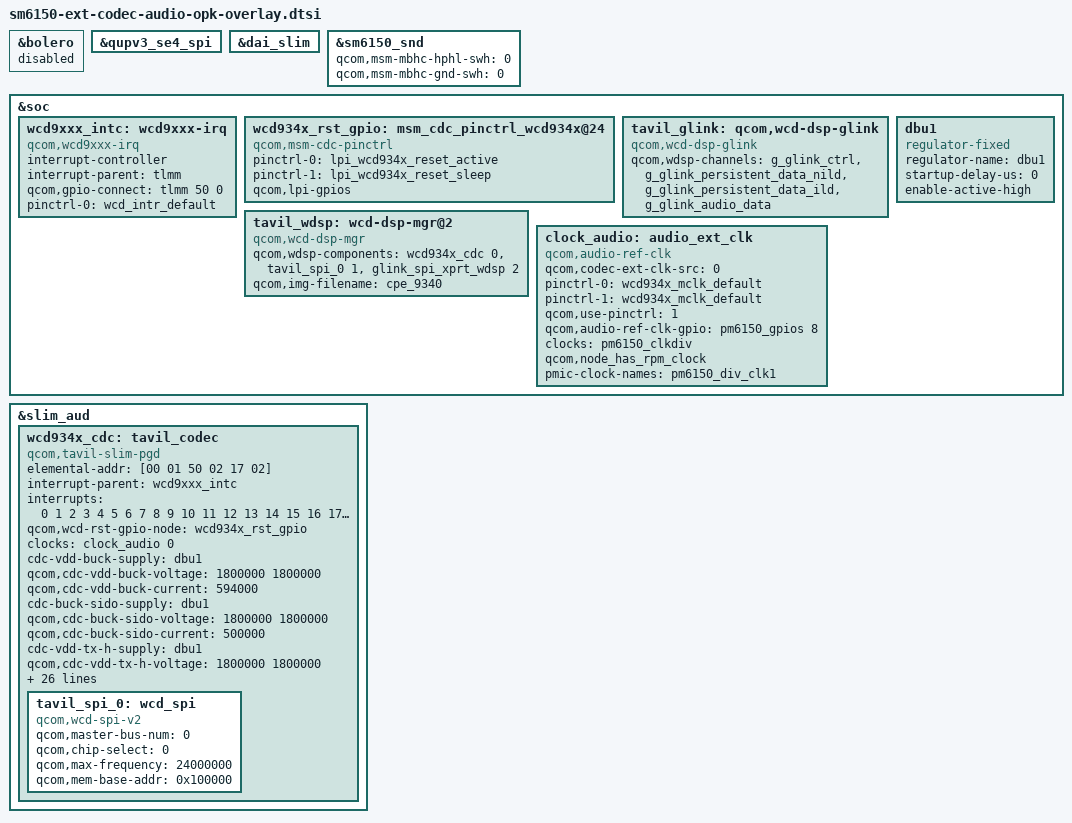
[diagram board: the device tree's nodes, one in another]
/*
 * Copyright (c) 2018-2019, 2021, The Linux Foundation. All rights reserved.
 *
 * This program is free software; you can redistribute it and/or modify
 * it under the terms of the GNU General Public License version 2 and
 * only version 2 as published by the Free Software Foundation.
 *
 * This program is distributed in the hope that it will be useful,
 * but WITHOUT ANY WARRANTY; without even the implied warranty of
 * MERCHANTABILITY or FITNESS FOR A PARTICULAR PURPOSE.  See the
 * GNU General Public License for more details.
 */

#include "sm6150-lpi.dtsi"
#include <dt-bindings/clock/qcom,audio-ext-clk.h>
#include <dt-bindings/sound/audio-codec-port-types.h>

&bolero {
	status = "disabled";
};

&qupv3_se4_spi {
	status = "okay";
};

&dai_slim {
	status = "okay";
};

&sm6150_snd {
	qcom,msm-mbhc-hphl-swh = <0>;
	qcom,msm-mbhc-gnd-swh = <0>;
};

&soc {
	wcd9xxx_intc: wcd9xxx-irq {
		status = "okay";
		compatible = "qcom,wcd9xxx-irq";
		interrupt-controller;
		#interrupt-cells = <1>;
		interrupt-parent = <&tlmm>;
		qcom,gpio-connect = <&tlmm 50 0>;
		pinctrl-names = "default";
		pinctrl-0 = <&wcd_intr_default>;
	};


	wcd934x_rst_gpio: msm_cdc_pinctrl_wcd934x@24 {
		status = "okay";
		compatible = "qcom,msm-cdc-pinctrl";
		pinctrl-names = "aud_active", "aud_sleep";
		pinctrl-0 = <&lpi_wcd934x_reset_active>;
		pinctrl-1 = <&lpi_wcd934x_reset_sleep>;
		qcom,lpi-gpios;
	};

	tavil_glink: qcom,wcd-dsp-glink {
		status = "okay";
		compatible = "qcom,wcd-dsp-glink";
		qcom,wdsp-channels = "g_glink_ctrl",
				     "g_glink_persistent_data_nild",
				     "g_glink_persistent_data_ild",
				     "g_glink_audio_data";
	};

	tavil_wdsp: wcd-dsp-mgr@2 {
		status = "okay";
		compatible = "qcom,wcd-dsp-mgr";
		qcom,wdsp-components = <&wcd934x_cdc 0>,
				       <&tavil_spi_0 1>,
				       <&glink_spi_xprt_wdsp 2>;
		qcom,img-filename = "cpe_9340";
	};

	clock_audio: audio_ext_clk {
		status = "okay";
		qcom,codec-ext-clk-src = <0>;
		compatible = "qcom,audio-ref-clk";
		pinctrl-names = "active", "sleep";
		pinctrl-0 = <&wcd934x_mclk_default>;
		pinctrl-1 = <&wcd934x_mclk_default>;
		qcom,use-pinctrl = <1>;
		qcom,audio-ref-clk-gpio = <&pm6150_gpios 8 0>;
		clock-names = "osr_clk";
		clocks = <&pm6150_clkdiv>;
		qcom,node_has_rpm_clock;
		pmic-clock-names = "pm6150_div_clk1";
		#clock-cells = <1>;
	};

	dbu1: dbu1 {
	    compatible = "regulator-fixed";
	    regulator-name = "dbu1";
	    startup-delay-us = <0>;
	    enable-active-high;
	};
};

&slim_aud {
	wcd934x_cdc: tavil_codec {
		status = "okay";
		compatible = "qcom,tavil-slim-pgd";
		elemental-addr = [00 01 50 02 17 02];

		interrupt-parent = <&wcd9xxx_intc>;
		interrupts = <0 1 2 3 4 5 6 7 8 9 10 11 12 13 14 15 16
			      17 18 19 20 21 22 23 24 25 26 27 28 29
			      30 31>;

		qcom,wcd-rst-gpio-node = <&wcd934x_rst_gpio>;

		clock-names = "wcd_clk";
		clocks = <&clock_audio 0>;

		cdc-vdd-buck-supply = <&dbu1>;
		qcom,cdc-vdd-buck-voltage = <1800000 1800000>;
		qcom,cdc-vdd-buck-current = <594000>;

		cdc-buck-sido-supply = <&dbu1>;
		qcom,cdc-buck-sido-voltage = <1800000 1800000>;
		qcom,cdc-buck-sido-current = <500000>;

		cdc-vdd-tx-h-supply = <&dbu1>;
		qcom,cdc-vdd-tx-h-voltage = <1800000 1800000>;
		qcom,cdc-vdd-tx-h-current = <25000>;

		cdc-vdd-rx-h-supply = <&dbu1>;
		qcom,cdc-vdd-rx-h-voltage = <1800000 1800000>;
		qcom,cdc-vdd-rx-h-current = <25000>;

		cdc-vddpx-1-supply = <&dbu1>;
		qcom,cdc-vddpx-1-voltage = <1800000 1800000>;
		qcom,cdc-vddpx-1-current = <10000>;

		cdc-vdd-mic-bias-supply = <&BOB>;
		qcom,cdc-vdd-mic-bias-voltage = <3296000 3296000>;
		qcom,cdc-vdd-mic-bias-current = <30400 1000001>;

		qcom,cdc-static-supplies = "cdc-vdd-buck",
					   "cdc-buck-sido",
					   "cdc-vdd-tx-h",
					   "cdc-vdd-rx-h",
					   "cdc-vddpx-1";
		qcom,cdc-on-demand-supplies = "cdc-vdd-mic-bias";

		qcom,cdc-micbias1-mv = <1800>;
		qcom,cdc-micbias2-mv = <1800>;
		qcom,cdc-micbias3-mv = <1800>;
		qcom,cdc-micbias4-mv = <1800>;

		qcom,cdc-mclk-clk-rate = <9600000>;
		qcom,cdc-slim-ifd = "tavil-slim-ifd";
		qcom,cdc-slim-ifd-elemental-addr = [00 00 50 02 17 02];
		qcom,cdc-dmic-sample-rate = <4800000>;
		qcom,cdc-mad-dmic-rate = <600000>;

		qcom,wdsp-cmpnt-dev-name = "tavil_codec";
		qcom,vreg-micb-supply = <&BOB>;

		tavil_spi_0: wcd_spi {
			compatible = "qcom,wcd-spi-v2";
			qcom,master-bus-num = <0>;
			qcom,chip-select = <0>;
			qcom,max-frequency = <24000000>;
			qcom,mem-base-addr = <0x100000>;
		};
	};
};
